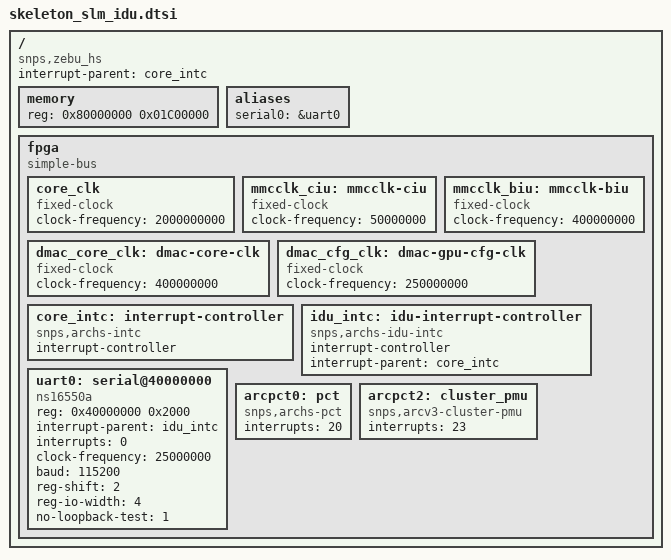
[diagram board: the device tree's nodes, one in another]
// SPDX-License-Identifier: GPL-2.0-only
/*
 * Copyright (C) 2023 Synopsys, Inc. (www.synopsys.com)
 */

/ {
	compatible = "snps,zebu_hs";
	#address-cells = <1>;
	#size-cells = <1>;
	interrupt-parent = <&core_intc>;

	memory {
		device_type = "memory";
                reg = <0x80000000 0x01C00000>;  /* 28 MB */
	};


	aliases {
		serial0 = &uart0;
	};

	fpga {
		compatible = "simple-bus";
		#address-cells = <1>;
		#size-cells = <1>;

		/* child and parent address space 1:1 mapped */
		ranges;

		core_clk: core_clk {
			#clock-cells = <0>;
			compatible = "fixed-clock";
			clock-frequency = <2000000000>;	/* 2 GHZ */
		};

		mmcclk_ciu: mmcclk-ciu {
			compatible = "fixed-clock";
			/*
			 * DW sdio controller has external ciu clock divider
			 * controlled via register in SDIO IP. Due to its
			 * unexpected default value (it should divide by 1
			 * but it divides by 8) SDIO IP uses wrong clock and
			 * works unstable (see STAR 9001204800)
			 * We switched to the minimum possible value of the
			 * divisor (div-by-2) in HSDK platform code.
			 * So add temporary fix and change clock frequency
			 * to 50000000 Hz until we fix dw sdio driver itself.
			 */
			clock-frequency = <50000000>;
			#clock-cells = <0>;
		};

		mmcclk_biu: mmcclk-biu {
			compatible = "fixed-clock";
			clock-frequency = <400000000>;
			#clock-cells = <0>;
		};

		dmac_core_clk: dmac-core-clk {
			compatible = "fixed-clock";
			clock-frequency = <400000000>;
			#clock-cells = <0>;
		};

		dmac_cfg_clk: dmac-gpu-cfg-clk {
			compatible = "fixed-clock";
			clock-frequency = <250000000>;
			#clock-cells = <0>;
		};
		core_intc: interrupt-controller {
			compatible = "snps,archs-intc";
			interrupt-controller;
			#interrupt-cells = <1>;
		};

		idu_intc: idu-interrupt-controller {
			compatible = "snps,archs-idu-intc";
			interrupt-controller;
			interrupt-parent = <&core_intc>;
			#interrupt-cells = <1>;
		};

		uart0: serial@40000000 {
			compatible = "ns16550a";
			reg = <0x40000000 0x2000>;
			interrupt-parent = <&idu_intc>;
			interrupts = <0>;
			clock-frequency = <25000000>;
			baud = <115200>;
			reg-shift = <2>;
			reg-io-width = <4>;
			no-loopback-test = <1>;
		};

		arcpct0: pct {
			compatible = "snps,archs-pct";
			#interrupt-cells = <1>;
			interrupts = <20>;
		};

		arcpct2: cluster_pmu {
			compatible = "snps,arcv3-cluster-pmu";
			#interrupt-cells = <1>;
			interrupts = <23>;
		};
	};
};
